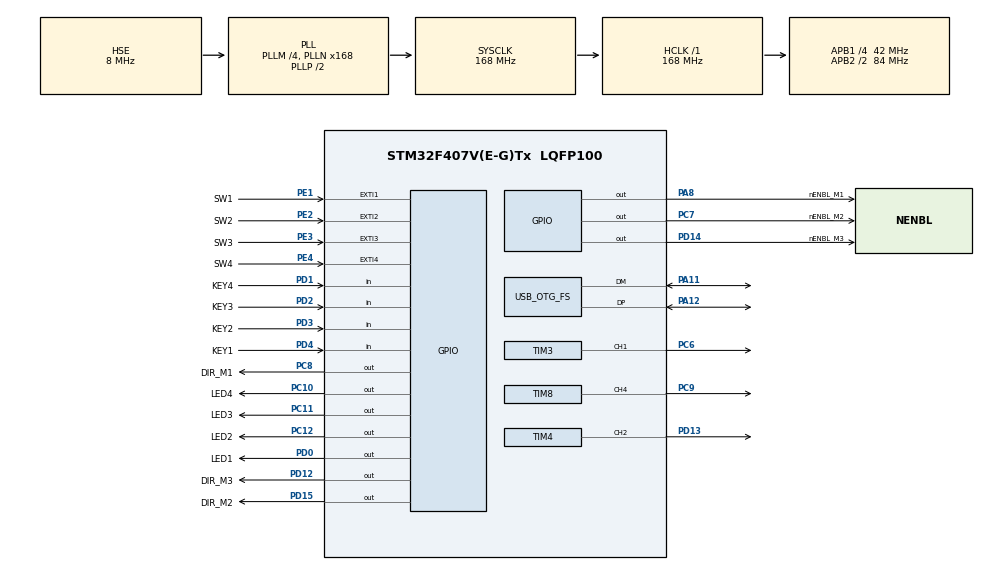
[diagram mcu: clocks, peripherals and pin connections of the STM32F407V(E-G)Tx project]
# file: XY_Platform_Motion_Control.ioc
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FREERTOS.Tasks01=defaultTask,24,128,StartDefaultTask,As weak,NULL,Dynamic,NULL,NULL;debugTask,24,512,StartDebugTask,As external,NULL,Dynamic,NULL,NULL;keyScanTask,16,128,StartKeyScanTask,As external,NULL,Dynamic,NULL,NULL;usbRxTask,24,512,StartUsbRxTask,As external,NULL,Dynamic,NULL,NULL
FREERTOS.configENABLE_FPU=1
FREERTOS.configTOTAL_HEAP_SIZE=16384
Mcu.Family=STM32F4
Mcu.Name=STM32F407V(E-G)Tx
Mcu.Package=LQFP100
Mcu.UserConstants=STIM_FREQ,1000000.0f
NVIC.EXTI1_IRQn=true\:5\:0\:false\:false\:true\:true\:true\:true\:true
NVIC.EXTI2_IRQn=true\:5\:0\:false\:false\:true\:true\:true\:true\:true
NVIC.EXTI3_IRQn=true\:5\:0\:false\:false\:true\:true\:true\:true\:true
NVIC.EXTI4_IRQn=true\:5\:0\:false\:false\:true\:true\:true\:true\:true
NVIC.OTG_FS_IRQn=true\:5\:0\:false\:false\:true\:true\:false\:true\:true
NVIC.PriorityGroup=NVIC_PRIORITYGROUP_4
NVIC.TIM1_TRG_COM_TIM11_IRQn=true\:15\:0\:false\:false\:true\:false\:false\:true\:true
NVIC.TIM3_IRQn=true\:5\:0\:false\:false\:true\:true\:true\:true\:true
NVIC.TIM4_IRQn=true\:5\:0\:false\:false\:true\:true\:true\:true\:true
NVIC.TIM8_TRG_COM_TIM14_IRQn=true\:5\:0\:false\:false\:true\:false\:false\:true\:true
NVIC.TIM8_UP_TIM13_IRQn=true\:5\:0\:false\:false\:true\:false\:false\:true\:true
NVIC.TimeBase=TIM1_TRG_COM_TIM11_IRQn
NVIC.TimeBaseIP=TIM11
PA11.Mode=Device_Only
PA11.Signal=USB_OTG_FS_DM
PA12.Mode=Device_Only
PA12.Signal=USB_OTG_FS_DP
PA13.Mode=Trace_Asynchronous_SW
PA13.Signal=SYS_JTMS-SWDIO
PA14.Mode=Trace_Asynchronous_SW
PA14.Signal=SYS_JTCK-SWCLK
PA8.GPIO_Label=nENBL_M1
PA8.Signal=GPIO_Output
PB3.Mode=Trace_Asynchronous_SW
PB3.Signal=SYS_JTDO-SWO
PC10.GPIO_Label=LED4
PC10.PinState=GPIO_PIN_SET
PC10.Signal=GPIO_Output
PC11.GPIO_Label=LED3
PC11.PinState=GPIO_PIN_SET
PC11.Signal=GPIO_Output
PC12.GPIO_Label=LED2
PC12.PinState=GPIO_PIN_SET
PC12.Signal=GPIO_Output
PC6.GPIO_PuPd=GPIO_PULLDOWN
PC6.Signal=S_TIM3_CH1
PC7.GPIO_Label=nENBL_M2
PC7.Signal=GPIO_Output
PC8.GPIO_Label=DIR_M1
PC8.GPIO_Speed=GPIO_SPEED_FREQ_VERY_HIGH
PC8.PinState=GPIO_PIN_SET
PC8.Signal=GPIO_Output
PC9.GPIO_PuPd=GPIO_PULLDOWN
PC9.Signal=S_TIM8_CH4
PD0.GPIO_Label=LED1
PD0.PinState=GPIO_PIN_SET
PD0.Signal=GPIO_Output
PD1.GPIO_Label=KEY4
PD1.Signal=GPIO_Input
PD12.GPIO_Label=DIR_M3
PD12.GPIO_Speed=GPIO_SPEED_FREQ_VERY_HIGH
PD12.PinState=GPIO_PIN_SET
PD12.Signal=GPIO_Output
PD13.GPIO_PuPd=GPIO_PULLDOWN
PD13.Signal=S_TIM4_CH2
PD14.GPIO_Label=nENBL_M3
PD14.Signal=GPIO_Output
PD15.GPIO_Label=DIR_M2
PD15.GPIO_Speed=GPIO_SPEED_FREQ_VERY_HIGH
PD15.PinState=GPIO_PIN_SET
PD15.Signal=GPIO_Output
PD2.GPIO_Label=KEY3
PD2.Signal=GPIO_Input
PD3.GPIO_Label=KEY2
PD3.Signal=GPIO_Input
PD4.GPIO_Label=KEY1
PD4.Signal=GPIO_Input
PE1.GPIO_Label=SW1
PE1.Signal=GPXTI1
PE2.GPIO_Label=SW2
PE2.Signal=GPXTI2
PE3.GPIO_Label=SW3
PE3.Signal=GPXTI3
PE4.GPIO_Label=SW4
PE4.Signal=GPXTI4
PH0-OSC_IN.Mode=HSE-External-Oscillator
PH0-OSC_IN.Signal=RCC_OSC_IN
PH1-OSC_OUT.Mode=HSE-External-Oscillator
PH1-OSC_OUT.Signal=RCC_OSC_OUT
ProjectManager.HeapSize=0x800
ProjectManager.StackSize=0x800
ProjectManager.TargetToolchain=MDK-ARM V5.32
RCC.48MHZClocksFreq_Value=48000000
RCC.AHBFreq_Value=168000000
RCC.APB1CLKDivider=RCC_HCLK_DIV4
RCC.APB1Freq_Value=42000000
RCC.APB1TimFreq_Value=84000000
RCC.APB2CLKDivider=RCC_HCLK_DIV2
RCC.APB2Freq_Value=84000000
RCC.APB2TimFreq_Value=168000000
RCC.CortexFreq_Value=168000000
RCC.HCLKFreq_Value=168000000
RCC.HSE_VALUE=8000000
RCC.HSI_VALUE=16000000
RCC.LSE_VALUE=32768
RCC.PLLM=4
RCC.PLLN=168
RCC.PLLQ=7
RCC.SYSCLKFreq_VALUE=168000000
RCC.SYSCLKSource=RCC_SYSCLKSOURCE_PLLCLK
RCC.VCOOutputFreq_Value=336000000
SH.S_TIM3_CH1.0=TIM3_CH1,PWM Generation1 CH1
SH.S_TIM4_CH2.0=TIM4_CH2,PWM Generation2 CH2
SH.S_TIM8_CH4.0=TIM8_CH4,PWM Generation4 CH4
TIM3.AutoReloadPreload=TIM_AUTORELOAD_PRELOAD_DISABLE
TIM3.Channel-PWM\ Generation1\ CH1=TIM_CHANNEL_1
TIM3.OCMode_PWM-PWM\ Generation1\ CH1=TIM_OCMODE_PWM1
TIM3.Period=999
TIM3.Prescaler=83
TIM3.Pulse-PWM\ Generation1\ CH1=0
TIM4.Channel-PWM\ Generation2\ CH2=TIM_CHANNEL_2
TIM4.OCMode_PWM-PWM\ Generation2\ CH2=TIM_OCMODE_PWM2
TIM4.Period=999
TIM4.Prescaler=83
TIM4.Pulse-PWM\ Generation2\ CH2=500
TIM8.Channel-PWM\ Generation4\ CH4=TIM_CHANNEL_4
TIM8.OCMode_PWM-PWM\ Generation4\ CH4=TIM_OCMODE_PWM2
TIM8.Period=999
TIM8.Prescaler=167
TIM8.Pulse-PWM\ Generation4\ CH4=500
USB_DEVICE.CLASS_NAME_FS=CDC
USB_DEVICE.VirtualMode-CDC_FS=Cdc
USB_DEVICE.VirtualModeFS=Cdc_FS
USB_OTG_FS.VirtualMode=Device_Only
VP_FREERTOS_VS_CMSIS_V2.Mode=CMSIS_V2
VP_SYS_VS_tim11.Mode=TIM11
VP_TIM4_VS_ClockSourceINT.Mode=Internal
VP_USB_DEVICE_VS_USB_DEVICE_CDC_FS.Mode=CDC_FS
board=custom

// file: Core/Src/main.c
/* USER CODE BEGIN Header */
/**
  ******************************************************************************
  * @file           : main.c
  * @brief          : Main program body
  ******************************************************************************
  * @attention
  *
  * Copyright (c) 2023 STMicroelectronics.
  * All rights reserved.
  *
  * This software is licensed under terms that can be found in the LICENSE file
  * in the root directory of this software component.
  * If no LICENSE file comes with this software, it is provided AS-IS.
  *
  ******************************************************************************
  */
/* USER CODE END Header */
#include "main.h"
#include "cmsis_os.h"
#include "tim.h"
#include "usb_device.h"
#include "gpio.h"

void SystemClock_Config(void);
void MX_FREERTOS_Init(void);
/* USER CODE BEGIN PFP */
extern void My_TIM_PeriodElapsedCallback(TIM_HandleTypeDef *htim);

int main(void)
{

  /* MCU Configuration--------------------------------------------------------*/

  /* Reset of all peripherals, Initializes the Flash interface and the Systick. */
  HAL_Init();

  /* Configure the system clock */
  SystemClock_Config();

  /* Initialize all configured peripherals */
  MX_GPIO_Init();
  MX_TIM3_Init();
  MX_TIM4_Init();
  MX_TIM8_Init();

  /* Init scheduler */
  osKernelInitialize();  /* Call init function for freertos objects (in cmsis_os2.c) */
  MX_FREERTOS_Init();

  /* Start scheduler */
  osKernelStart();

  /* We should never get here as control is now taken by the scheduler */

  /* Infinite loop */
  while (1)
  {

  }
}

void SystemClock_Config(void)
{
  RCC_OscInitTypeDef RCC_OscInitStruct = {0};
  RCC_ClkInitTypeDef RCC_ClkInitStruct = {0};

  /** Configure the main internal regulator output voltage
  */
  __HAL_RCC_PWR_CLK_ENABLE();
  __HAL_PWR_VOLTAGESCALING_CONFIG(PWR_REGULATOR_VOLTAGE_SCALE1);

  /** Initializes the RCC Oscillators according to the specified parameters
  * in the RCC_OscInitTypeDef structure.
  */
  RCC_OscInitStruct.OscillatorType = RCC_OSCILLATORTYPE_HSE;
  RCC_OscInitStruct.HSEState = RCC_HSE_ON;
  RCC_OscInitStruct.PLL.PLLState = RCC_PLL_ON;
  RCC_OscInitStruct.PLL.PLLSource = RCC_PLLSOURCE_HSE;
  RCC_OscInitStruct.PLL.PLLM = 4;
  RCC_OscInitStruct.PLL.PLLN = 168;
  RCC_OscInitStruct.PLL.PLLP = RCC_PLLP_DIV2;
  RCC_OscInitStruct.PLL.PLLQ = 7;
  if (HAL_RCC_OscConfig(&RCC_OscInitStruct) != HAL_OK)
  {
    Error_Handler();
  }

  /** Initializes the CPU, AHB and APB buses clocks
  */
  RCC_ClkInitStruct.ClockType = RCC_CLOCKTYPE_HCLK|RCC_CLOCKTYPE_SYSCLK
                              |RCC_CLOCKTYPE_PCLK1|RCC_CLOCKTYPE_PCLK2;
  RCC_ClkInitStruct.SYSCLKSource = RCC_SYSCLKSOURCE_PLLCLK;
  RCC_ClkInitStruct.AHBCLKDivider = RCC_SYSCLK_DIV1;
  RCC_ClkInitStruct.APB1CLKDivider = RCC_HCLK_DIV4;
  RCC_ClkInitStruct.APB2CLKDivider = RCC_HCLK_DIV2;

  if (HAL_RCC_ClockConfig(&RCC_ClkInitStruct, FLASH_LATENCY_5) != HAL_OK)
  {
    Error_Handler();
  }
}

void HAL_TIM_PeriodElapsedCallback(TIM_HandleTypeDef *htim)
{
  if (htim->Instance == TIM11)
  {
    HAL_IncTick();
  }
  /* USER CODE BEGIN Callback 1 */
  My_TIM_PeriodElapsedCallback(htim);

  /* USER CODE END Callback 1 */
}

void Error_Handler(void)
{
  __disable_irq();
  while (1)
  {
  }
}

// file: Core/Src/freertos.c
/* USER CODE BEGIN Header */
/**
  ******************************************************************************
  * File Name          : freertos.c
  * Description        : Code for freertos applications
  ******************************************************************************
  * @attention
  *
  * Copyright (c) 2023 STMicroelectronics.
  * All rights reserved.
  *
  * This software is licensed under terms that can be found in the LICENSE file
  * in the root directory of this software component.
  * If no LICENSE file comes with this software, it is provided AS-IS.
  *
  ******************************************************************************
  */
/* USER CODE END Header */

#include "FreeRTOS.h"
#include "task.h"
#include "main.h"
#include "cmsis_os.h"

/* Definitions for defaultTask */
osThreadId_t defaultTaskHandle;
const osThreadAttr_t defaultTask_attributes = {
  .name = "defaultTask",
  .stack_size = 128 * 4,
  .priority = (osPriority_t) osPriorityNormal,
};
/* Definitions for debugTask */
osThreadId_t debugTaskHandle;
const osThreadAttr_t debugTask_attributes = {
  .name = "debugTask",
  .stack_size = 512 * 4,
  .priority = (osPriority_t) osPriorityNormal,
};
/* Definitions for keyScanTask */
osThreadId_t keyScanTaskHandle;
const osThreadAttr_t keyScanTask_attributes = {
  .name = "keyScanTask",
  .stack_size = 128 * 4,
  .priority = (osPriority_t) osPriorityBelowNormal,
};

void StartDefaultTask(void *argument);
extern void StartDebugTask(void *argument);
extern void StartKeyScanTask(void *argument);

extern void MX_USB_DEVICE_Init(void);
void MX_FREERTOS_Init(void); /* (MISRA C 2004 rule 8.1) */

void MX_FREERTOS_Init(void) {

  /* Create the thread(s) */
  /* creation of defaultTask */
  defaultTaskHandle = osThreadNew(StartDefaultTask, NULL, &defaultTask_attributes);

  /* creation of debugTask */
  debugTaskHandle = osThreadNew(StartDebugTask, NULL, &debugTask_attributes);

  /* creation of keyScanTask */
  keyScanTaskHandle = osThreadNew(StartKeyScanTask, NULL, &keyScanTask_attributes);

  /* USER CODE BEGIN RTOS_THREADS */
  /* add threads, ... */
  osThreadSuspend(debugTaskHandle);
  osThreadSuspend(keyScanTaskHandle);
  /* USER CODE END RTOS_THREADS */

}

__weak void StartDefaultTask(void *argument)
{
  /* init code for USB_DEVICE */
  MX_USB_DEVICE_Init();
  for(;;)
  {
    osDelay(1);
  }
}
